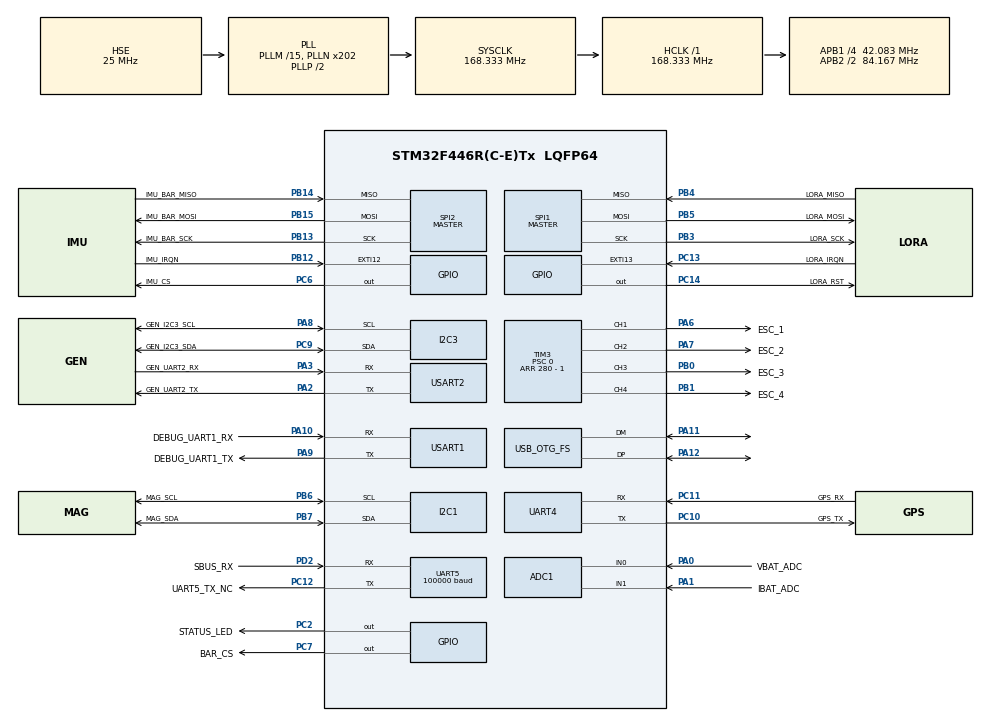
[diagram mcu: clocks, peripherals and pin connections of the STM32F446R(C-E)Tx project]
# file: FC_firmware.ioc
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ADC1.Channel-6\#ChannelRegularConversion=ADC_CHANNEL_0
ADC1.Channel-7\#ChannelRegularConversion=ADC_CHANNEL_1
ADC1.ClockPrescaler=ADC_CLOCK_SYNC_PCLK_DIV8
ADC1.ContinuousConvMode=ENABLE
ADC1.DMAContinuousRequests=ENABLE
ADC1.EOCSelection=ADC_EOC_SEQ_CONV
ADC1.NbrOfConversion=2
ADC1.NbrOfConversionFlag=1
ADC1.Rank-6\#ChannelRegularConversion=1
ADC1.Rank-7\#ChannelRegularConversion=2
ADC1.SamplingTime-6\#ChannelRegularConversion=ADC_SAMPLETIME_480CYCLES
ADC1.SamplingTime-7\#ChannelRegularConversion=ADC_SAMPLETIME_480CYCLES
ADC1.ScanConvMode=ENABLE
ADC1.master=1
Dma.ADC1.4.Direction=DMA_PERIPH_TO_MEMORY
Dma.ADC1.4.FIFOMode=DMA_FIFOMODE_DISABLE
Dma.ADC1.4.Instance=DMA2_Stream0
Dma.ADC1.4.MemDataAlignment=DMA_MDATAALIGN_WORD
Dma.ADC1.4.MemInc=DMA_MINC_ENABLE
Dma.ADC1.4.Mode=DMA_CIRCULAR
Dma.ADC1.4.PeriphDataAlignment=DMA_PDATAALIGN_WORD
Dma.ADC1.4.PeriphInc=DMA_PINC_DISABLE
Dma.ADC1.4.Priority=DMA_PRIORITY_LOW
Dma.Request0=USART1_TX
Dma.Request1=USART1_RX
Dma.Request2=SPI2_RX
Dma.Request3=UART5_RX
Dma.Request4=ADC1
Dma.Request5=TIM3_CH4/UP
Dma.Request6=SPI2_TX
Dma.Request7=USART2_RX
Dma.Request8=USART2_TX
Dma.SPI2_RX.2.Direction=DMA_PERIPH_TO_MEMORY
Dma.SPI2_RX.2.FIFOMode=DMA_FIFOMODE_DISABLE
Dma.SPI2_RX.2.Instance=DMA1_Stream3
Dma.SPI2_RX.2.MemDataAlignment=DMA_MDATAALIGN_BYTE
Dma.SPI2_RX.2.MemInc=DMA_MINC_ENABLE
Dma.SPI2_RX.2.Mode=DMA_NORMAL
Dma.SPI2_RX.2.PeriphDataAlignment=DMA_PDATAALIGN_BYTE
Dma.SPI2_RX.2.PeriphInc=DMA_PINC_DISABLE
Dma.SPI2_RX.2.Priority=DMA_PRIORITY_HIGH
Dma.SPI2_TX.6.Direction=DMA_MEMORY_TO_PERIPH
Dma.SPI2_TX.6.FIFOMode=DMA_FIFOMODE_DISABLE
Dma.SPI2_TX.6.Instance=DMA1_Stream4
Dma.SPI2_TX.6.MemDataAlignment=DMA_MDATAALIGN_BYTE
Dma.SPI2_TX.6.MemInc=DMA_MINC_ENABLE
Dma.SPI2_TX.6.Mode=DMA_NORMAL
Dma.SPI2_TX.6.PeriphDataAlignment=DMA_PDATAALIGN_BYTE
Dma.SPI2_TX.6.PeriphInc=DMA_PINC_DISABLE
Dma.SPI2_TX.6.Priority=DMA_PRIORITY_HIGH
Dma.TIM3_CH4/UP.5.Direction=DMA_MEMORY_TO_PERIPH
Dma.TIM3_CH4/UP.5.FIFOMode=DMA_FIFOMODE_DISABLE
Dma.TIM3_CH4/UP.5.Instance=DMA1_Stream2
Dma.TIM3_CH4/UP.5.MemDataAlignment=DMA_MDATAALIGN_WORD
Dma.TIM3_CH4/UP.5.MemInc=DMA_MINC_ENABLE
Dma.TIM3_CH4/UP.5.Mode=DMA_NORMAL
Dma.TIM3_CH4/UP.5.PeriphDataAlignment=DMA_PDATAALIGN_WORD
Dma.TIM3_CH4/UP.5.PeriphInc=DMA_PINC_DISABLE
Dma.TIM3_CH4/UP.5.Priority=DMA_PRIORITY_HIGH
Dma.UART5_RX.3.Direction=DMA_PERIPH_TO_MEMORY
Dma.UART5_RX.3.FIFOMode=DMA_FIFOMODE_DISABLE
Dma.UART5_RX.3.Instance=DMA1_Stream0
Dma.UART5_RX.3.MemDataAlignment=DMA_MDATAALIGN_BYTE
Dma.UART5_RX.3.MemInc=DMA_MINC_ENABLE
Dma.UART5_RX.3.Mode=DMA_NORMAL
Dma.UART5_RX.3.PeriphDataAlignment=DMA_PDATAALIGN_BYTE
Dma.UART5_RX.3.PeriphInc=DMA_PINC_DISABLE
Dma.UART5_RX.3.Priority=DMA_PRIORITY_LOW
Dma.USART1_RX.1.Direction=DMA_PERIPH_TO_MEMORY
Dma.USART1_RX.1.FIFOMode=DMA_FIFOMODE_DISABLE
Dma.USART1_RX.1.Instance=DMA2_Stream2
Dma.USART1_RX.1.MemDataAlignment=DMA_MDATAALIGN_BYTE
Dma.USART1_RX.1.MemInc=DMA_MINC_ENABLE
Dma.USART1_RX.1.Mode=DMA_CIRCULAR
Dma.USART1_RX.1.PeriphDataAlignment=DMA_PDATAALIGN_BYTE
Dma.USART1_RX.1.PeriphInc=DMA_PINC_DISABLE
Dma.USART1_RX.1.Priority=DMA_PRIORITY_LOW
Dma.USART1_TX.0.Direction=DMA_MEMORY_TO_PERIPH
Dma.USART1_TX.0.FIFOMode=DMA_FIFOMODE_DISABLE
Dma.USART1_TX.0.Instance=DMA2_Stream7
Dma.USART1_TX.0.MemDataAlignment=DMA_MDATAALIGN_BYTE
Dma.USART1_TX.0.MemInc=DMA_MINC_ENABLE
Dma.USART1_TX.0.Mode=DMA_NORMAL
Dma.USART1_TX.0.PeriphDataAlignment=DMA_PDATAALIGN_BYTE
Dma.USART1_TX.0.PeriphInc=DMA_PINC_DISABLE
Dma.USART1_TX.0.Priority=DMA_PRIORITY_LOW
Dma.USART2_RX.7.Direction=DMA_PERIPH_TO_MEMORY
Dma.USART2_RX.7.FIFOMode=DMA_FIFOMODE_DISABLE
Dma.USART2_RX.7.Instance=DMA1_Stream5
Dma.USART2_RX.7.MemDataAlignment=DMA_MDATAALIGN_BYTE
Dma.USART2_RX.7.MemInc=DMA_MINC_ENABLE
Dma.USART2_RX.7.Mode=DMA_NORMAL
Dma.USART2_RX.7.PeriphDataAlignment=DMA_PDATAALIGN_BYTE
Dma.USART2_RX.7.PeriphInc=DMA_PINC_DISABLE
Dma.USART2_RX.7.Priority=DMA_PRIORITY_LOW
Dma.USART2_TX.8.Direction=DMA_MEMORY_TO_PERIPH
Dma.USART2_TX.8.FIFOMode=DMA_FIFOMODE_DISABLE
Dma.USART2_TX.8.Instance=DMA1_Stream6
Dma.USART2_TX.8.MemDataAlignment=DMA_MDATAALIGN_BYTE
Dma.USART2_TX.8.MemInc=DMA_MINC_ENABLE
Dma.USART2_TX.8.Mode=DMA_NORMAL
Dma.USART2_TX.8.PeriphDataAlignment=DMA_PDATAALIGN_BYTE
Dma.USART2_TX.8.PeriphInc=DMA_PINC_DISABLE
Dma.USART2_TX.8.Priority=DMA_PRIORITY_LOW
Mcu.Family=STM32F4
Mcu.Name=STM32F446R(C-E)Tx
Mcu.Package=LQFP64
NVIC.DMA1_Stream0_IRQn=true\:0\:0\:false\:false\:true\:false\:true\:true
NVIC.DMA1_Stream2_IRQn=true\:0\:0\:false\:false\:true\:false\:true\:true
NVIC.DMA1_Stream3_IRQn=true\:0\:0\:false\:false\:true\:false\:true\:true
NVIC.DMA1_Stream4_IRQn=true\:0\:0\:false\:false\:true\:false\:true\:true
NVIC.DMA1_Stream5_IRQn=true\:0\:0\:false\:false\:true\:false\:true\:true
NVIC.DMA1_Stream6_IRQn=true\:0\:0\:false\:false\:true\:false\:true\:true
NVIC.DMA2_Stream0_IRQn=true\:0\:0\:false\:false\:true\:false\:true\:true
NVIC.DMA2_Stream2_IRQn=true\:0\:0\:false\:false\:true\:false\:true\:true
NVIC.DMA2_Stream7_IRQn=true\:0\:0\:false\:false\:true\:false\:true\:true
NVIC.PriorityGroup=NVIC_PRIORITYGROUP_4
NVIC.SPI2_IRQn=true\:0\:0\:false\:false\:true\:true\:true\:true
NVIC.TIM1_UP_TIM10_IRQn=true\:0\:0\:false\:false\:true\:true\:true\:true
NVIC.TIM2_IRQn=true\:0\:0\:false\:false\:true\:true\:true\:true
NVIC.UART5_IRQn=true\:0\:0\:false\:false\:true\:true\:true\:true
NVIC.USART1_IRQn=true\:0\:0\:false\:false\:true\:true\:true\:true
NVIC.USART2_IRQn=true\:0\:0\:false\:false\:true\:true\:true\:true
PA0-WKUP.GPIO_Label=VBAT_ADC
PA0-WKUP.Signal=ADCx_IN0
PA1.GPIO_Label=IBAT_ADC
PA1.Signal=ADCx_IN1
PA10.GPIO_Label=DEBUG_UART1_RX
PA10.Mode=Asynchronous
PA10.Signal=USART1_RX
PA11.Mode=Device_Only
PA11.Signal=USB_OTG_FS_DM
PA12.Mode=Device_Only
PA12.Signal=USB_OTG_FS_DP
PA13.Mode=Serial_Wire
PA13.Signal=SYS_JTMS-SWDIO
PA14.Mode=Serial_Wire
PA14.Signal=SYS_JTCK-SWCLK
PA2.GPIO_Label=GEN_UART2_TX
PA2.Mode=Asynchronous
PA2.Signal=USART2_TX
PA3.GPIO_Label=GEN_UART2_RX
PA3.Mode=Asynchronous
PA3.Signal=USART2_RX
PA5.GPIO_Label=GEN_TIM2_CH1
PA5.Signal=S_TIM2_CH1_ETR
PA6.GPIO_Label=ESC_1
PA6.Signal=S_TIM3_CH1
PA7.GPIO_Label=ESC_2
PA7.Signal=S_TIM3_CH2
PA8.GPIO_Label=GEN_I2C3_SCL
PA8.Mode=I2C
PA8.Signal=I2C3_SCL
PA9.GPIO_Label=DEBUG_UART1_TX
PA9.Mode=Asynchronous
PA9.Signal=USART1_TX
PB0.GPIO_Label=ESC_3
PB0.Signal=S_TIM3_CH3
PB1.GPIO_Label=ESC_4
PB1.Signal=S_TIM3_CH4
PB10.GPIO_Label=GEN_TIM2_CH3
PB10.Signal=S_TIM2_CH3
PB12.GPIO_Label=IMU_IRQN
PB12.Signal=GPXTI12
PB13.GPIO_Label=IMU_BAR_SCK
PB13.Mode=Full_Duplex_Master
PB13.Signal=SPI2_SCK
PB14.GPIO_Label=IMU_BAR_MISO
PB14.Mode=Full_Duplex_Master
PB14.Signal=SPI2_MISO
PB15.GPIO_Label=IMU_BAR_MOSI
PB15.Mode=Full_Duplex_Master
PB15.Signal=SPI2_MOSI
PB2.GPIO_Label=GEN_TIM2_CH4
PB2.Signal=S_TIM2_CH4
PB3.GPIO_Label=LORA_SCK
PB3.Mode=Full_Duplex_Master
PB3.Signal=SPI1_SCK
PB4.GPIO_Label=LORA_MISO
PB4.Mode=Full_Duplex_Master
PB4.Signal=SPI1_MISO
PB5.GPIO_Label=LORA_MOSI
PB5.Mode=Full_Duplex_Master
PB5.Signal=SPI1_MOSI
PB6.GPIO_Label=MAG_SCL
PB6.Mode=I2C
PB6.Signal=I2C1_SCL
PB7.GPIO_Label=MAG_SDA
PB7.Mode=I2C
PB7.Signal=I2C1_SDA
PB8.GPIO_Label=GEN_TIM10_CH1
PB8.Signal=S_TIM10_CH1
PB9.GPIO_Label=GEN_TIM2_CH2
PB9.Signal=S_TIM2_CH2
PC10.GPIO_Label=GPS_TX
PC10.Mode=Asynchronous
PC10.Signal=UART4_TX
PC11.GPIO_Label=GPS_RX
PC11.Mode=Asynchronous
PC11.Signal=UART4_RX
PC12.GPIO_Label=UART5_TX_NC
PC12.Mode=Asynchronous
PC12.Signal=UART5_TX
PC13.GPIO_Label=LORA_IRQN
PC13.Signal=GPXTI13
PC14-OSC32_IN.GPIO_Label=LORA_RST
PC14-OSC32_IN.Signal=GPIO_Output
PC2.GPIO_Label=STATUS_LED
PC2.Signal=GPIO_Output
PC6.GPIO_Label=IMU_CS
PC6.Signal=GPIO_Output
PC7.GPIO_Label=BAR_CS
PC7.Signal=GPIO_Output
PC8.GPIO_Label=GEN_TIM8_CH3
PC8.Signal=S_TIM8_CH3
PC9.GPIO_Label=GEN_I2C3_SDA
PC9.Mode=I2C
PC9.Signal=I2C3_SDA
PD2.GPIO_Label=SBUS_RX
PD2.Mode=Asynchronous
PD2.Signal=UART5_RX
PH0-OSC_IN.Mode=HSE-External-Oscillator
PH0-OSC_IN.Signal=RCC_OSC_IN
PH1-OSC_OUT.Mode=HSE-External-Oscillator
PH1-OSC_OUT.Signal=RCC_OSC_OUT
ProjectManager.HeapSize=0x200
ProjectManager.StackSize=0x1000
ProjectManager.TargetToolchain=STM32CubeIDE
RCC.AHBFreq_Value=168333333.33333334
RCC.APB1CLKDivider=RCC_HCLK_DIV4
RCC.APB1Freq_Value=42083333.333333336
RCC.APB1TimFreq_Value=84166666.66666667
RCC.APB2CLKDivider=RCC_HCLK_DIV2
RCC.APB2Freq_Value=84166666.66666667
RCC.APB2TimFreq_Value=168333333.33333334
RCC.CortexFreq_Value=168333333.33333334
RCC.HCLKFreq_Value=168333333.33333334
RCC.PLLM=15
RCC.PLLN=202
RCC.PLLQ=7
RCC.PLLSourceVirtual=RCC_PLLSOURCE_HSE
RCC.SYSCLKFreq_VALUE=168333333.33333334
RCC.SYSCLKSource=RCC_SYSCLKSOURCE_PLLCLK
RCC.USBFreq_Value=48095238.0952381
RCC.VCOOutputFreq_Value=336666666.6666667
SH.ADCx_IN0.0=ADC1_IN0,IN0
SH.ADCx_IN1.0=ADC1_IN1,IN1
SH.S_TIM10_CH1.0=TIM10_CH1
SH.S_TIM2_CH1_ETR.0=TIM2_CH1
SH.S_TIM2_CH2.0=TIM2_CH2
SH.S_TIM2_CH3.0=TIM2_CH3
SH.S_TIM2_CH4.0=TIM2_CH4
SH.S_TIM3_CH1.0=TIM3_CH1,PWM Generation1 CH1
SH.S_TIM3_CH2.0=TIM3_CH2,PWM Generation2 CH2
SH.S_TIM3_CH3.0=TIM3_CH3,PWM Generation3 CH3
SH.S_TIM3_CH4.0=TIM3_CH4,PWM Generation4 CH4
SH.S_TIM8_CH3.0=TIM8_CH3
SPI1.BaudRatePrescaler=SPI_BAUDRATEPRESCALER_2
SPI1.CalculateBaudRate=42.083332 MBits/s
SPI1.Direction=SPI_DIRECTION_2LINES
SPI1.Mode=SPI_MODE_MASTER
SPI1.VirtualType=VM_MASTER
SPI2.BaudRatePrescaler=SPI_BAUDRATEPRESCALER_4
SPI2.CalculateBaudRate=10.520833 MBits/s
SPI2.Direction=SPI_DIRECTION_2LINES
SPI2.Mode=SPI_MODE_MASTER
SPI2.VirtualType=VM_MASTER
TIM10.Period=1000
TIM10.Prescaler=12
TIM2.Period=4294967295
TIM2.Prescaler=84
TIM3.Channel-PWM\ Generation1\ CH1=TIM_CHANNEL_1
TIM3.Channel-PWM\ Generation2\ CH2=TIM_CHANNEL_2
TIM3.Channel-PWM\ Generation3\ CH3=TIM_CHANNEL_3
TIM3.Channel-PWM\ Generation4\ CH4=TIM_CHANNEL_4
TIM3.CounterMode=TIM_COUNTERMODE_UP
TIM3.OCPolarity_1=TIM_OCPOLARITY_HIGH
TIM3.OCPolarity_2=TIM_OCPOLARITY_HIGH
TIM3.OCPolarity_3=TIM_OCPOLARITY_HIGH
TIM3.OCPolarity_4=TIM_OCPOLARITY_HIGH
TIM3.Period=280 - 1
TIM3.Prescaler=0
UART4.VirtualMode=Asynchronous
UART5.BaudRate=100000
UART5.Mode=MODE_RX
UART5.Parity=PARITY_EVEN
UART5.StopBits=UART_STOPBITS_2
UART5.VirtualMode=Asynchronous
UART5.WordLength=WORDLENGTH_9B
USART1.VirtualMode=VM_ASYNC
USART2.VirtualMode=VM_ASYNC
USB_OTG_FS.VirtualMode=Device_Only
VP_TIM10_VS_ClockSourceINT.Mode=Enable_Timer
VP_TIM2_VS_ClockSourceINT.Mode=Internal
VP_TIM3_VS_ClockSourceINT.Mode=Internal
board=custom

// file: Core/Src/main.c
/* USER CODE BEGIN Header */
/**
 ******************************************************************************
 * @file           : main.c
 * @brief          : Main program body
 ******************************************************************************
 * @attention
 *
 * Copyright (c) 2025 STMicroelectronics.
 * All rights reserved.
 *
 * This software is licensed under terms that can be found in the LICENSE file
 * in the root directory of this software component.
 * If no LICENSE file comes with this software, it is provided AS-IS.
 *
 ******************************************************************************
 */
/* USER CODE END Header */
#include "main.h"
#include "adc.h"
#include "dma.h"
#include "gpio.h"
#include "i2c.h"
#include "spi.h"
#include "tim.h"
#include "usart.h"
#include "usb_otg.h"

/* USER CODE BEGIN Includes */
#include "err/err.h"
#include "sys/sys.h"

#include <inttypes.h>
#include <stdio.h>

// ugly but needed
#include "irq/impl/irq_handler.c"

/* USER CODE END Includes */

void SystemClock_Config(void);

int main(void) {

    /* MCU Configuration--------------------------------------------------------*/

    /* Reset of all peripherals, Initializes the Flash interface and the Systick. */
    HAL_Init();

    /* Configure the system clock */
    SystemClock_Config();

    /* Initialize all configured peripherals */
    MX_GPIO_Init();
    MX_DMA_Init();
    MX_USART1_UART_Init();
    MX_I2C1_Init();
    MX_SPI1_Init();
    MX_SPI2_Init();
    MX_TIM3_Init();
    MX_UART4_Init();
    MX_USART2_UART_Init();
    MX_ADC1_Init();
    MX_I2C3_Init();
    MX_TIM2_Init();
    MX_TIM10_Init();
    MX_UART5_Init();
    MX_USB_OTG_FS_PCD_Init();
    /* USER CODE BEGIN 2 */
    // TODO: disable USB OTG?
    sys_entry();
    /* USER CODE END 2 */

    /* Infinite loop */
    while (1) {

    }
}

void SystemClock_Config(void) {
    RCC_OscInitTypeDef RCC_OscInitStruct = { 0 };
    RCC_ClkInitTypeDef RCC_ClkInitStruct = { 0 };

    /** Configure the main internal regulator output voltage
     */
    __HAL_RCC_PWR_CLK_ENABLE();
    __HAL_PWR_VOLTAGESCALING_CONFIG(PWR_REGULATOR_VOLTAGE_SCALE1);

    /** Initializes the RCC Oscillators according to the specified parameters
     * in the RCC_OscInitTypeDef structure.
     */
    RCC_OscInitStruct.OscillatorType = RCC_OSCILLATORTYPE_HSE;
    RCC_OscInitStruct.HSEState = RCC_HSE_ON;
    RCC_OscInitStruct.PLL.PLLState = RCC_PLL_ON;
    RCC_OscInitStruct.PLL.PLLSource = RCC_PLLSOURCE_HSE;
    RCC_OscInitStruct.PLL.PLLM = 15;
    RCC_OscInitStruct.PLL.PLLN = 202;
    RCC_OscInitStruct.PLL.PLLP = RCC_PLLP_DIV2;
    RCC_OscInitStruct.PLL.PLLQ = 7;
    RCC_OscInitStruct.PLL.PLLR = 2;
    if (HAL_RCC_OscConfig(&RCC_OscInitStruct) != HAL_OK) {
        Error_Handler();
    }

    /** Activate the Over-Drive mode
     */
    if (HAL_PWREx_EnableOverDrive() != HAL_OK) {
        Error_Handler();
    }

    /** Initializes the CPU, AHB and APB buses clocks
     */
    RCC_ClkInitStruct.ClockType = RCC_CLOCKTYPE_HCLK | RCC_CLOCKTYPE_SYSCLK | RCC_CLOCKTYPE_PCLK1 | RCC_CLOCKTYPE_PCLK2;
    RCC_ClkInitStruct.SYSCLKSource = RCC_SYSCLKSOURCE_PLLCLK;
    RCC_ClkInitStruct.AHBCLKDivider = RCC_SYSCLK_DIV1;
    RCC_ClkInitStruct.APB1CLKDivider = RCC_HCLK_DIV4;
    RCC_ClkInitStruct.APB2CLKDivider = RCC_HCLK_DIV2;

    if (HAL_RCC_ClockConfig(&RCC_ClkInitStruct, FLASH_LATENCY_5) != HAL_OK) {
        Error_Handler();
    }
}

void Error_Handler(void) {
    __disable_irq();
    while (1) {
    }
}
#ifdef USE_FULL_ASSERT
/**
 * @brief  Reports the name of the source file and the source line number
 *         where the assert_param error has occurred.
 * @param  file: pointer to the source file name
 * @param  line: assert_param error line source number
 * @retval None
 */
void assert_failed(uint8_t* file, uint32_t line) {
    /* USER CODE BEGIN 6 */
    char buf[128];

    int ret = snprintf(buf, sizeof(buf), "HAL assert failed (%s:%" PRIu32 ")", (const char*) file, line);
    if (ret > 0)
        err_handle_fatal(buf);
    else
        err_fatal("HAL assert failed, but we couldn't even format the error...");
    /* USER CODE END 6 */
}
#endif /* USE_FULL_ASSERT */
